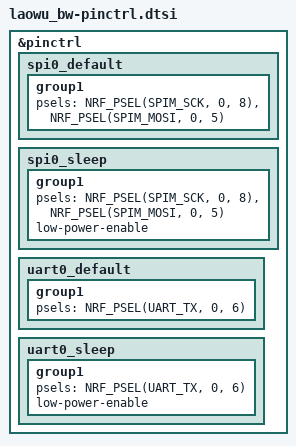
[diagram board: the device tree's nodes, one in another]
/*
 * Copyright (c) 2026 Cremind
 * SPDX-License-Identifier: MIT
 *
 * Pins from hardware/matrix.yaml (laowu_bw), decimal port-0 numbers.
 */

&pinctrl {
	spi0_default: spi0_default {
		group1 {
			psels = <NRF_PSEL(SPIM_SCK, 0, 8)>,
				<NRF_PSEL(SPIM_MOSI, 0, 5)>;
		};
	};

	spi0_sleep: spi0_sleep {
		group1 {
			psels = <NRF_PSEL(SPIM_SCK, 0, 8)>,
				<NRF_PSEL(SPIM_MOSI, 0, 5)>;
			low-power-enable;
		};
	};

	uart0_default: uart0_default {
		group1 {
			psels = <NRF_PSEL(UART_TX, 0, 6)>;
		};
	};

	uart0_sleep: uart0_sleep {
		group1 {
			psels = <NRF_PSEL(UART_TX, 0, 6)>;
			low-power-enable;
		};
	};
};
